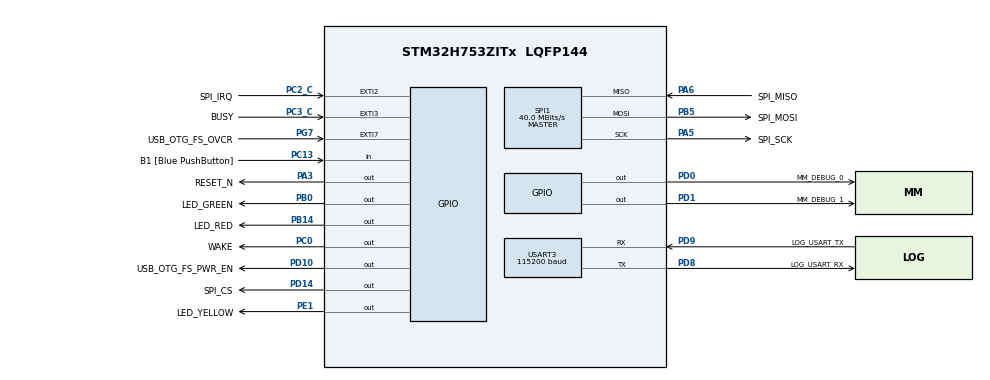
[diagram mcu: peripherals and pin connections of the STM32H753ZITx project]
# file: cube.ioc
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CORTEX_M7.CPU_DCache=Disabled
CORTEX_M7.CPU_ICache=Disabled
CORTEX_M7.MPU_Control=__NULL
Dma.Request0=SPI1_TX
Dma.Request1=SPI1_RX
Dma.SPI1_RX.1.Direction=DMA_PERIPH_TO_MEMORY
Dma.SPI1_RX.1.EventEnable=DISABLE
Dma.SPI1_RX.1.FIFOMode=DMA_FIFOMODE_ENABLE
Dma.SPI1_RX.1.FIFOThreshold=DMA_FIFO_THRESHOLD_FULL
Dma.SPI1_RX.1.Instance=DMA1_Stream1
Dma.SPI1_RX.1.MemBurst=DMA_MBURST_SINGLE
Dma.SPI1_RX.1.MemDataAlignment=DMA_MDATAALIGN_BYTE
Dma.SPI1_RX.1.MemInc=DMA_MINC_ENABLE
Dma.SPI1_RX.1.Mode=DMA_NORMAL
Dma.SPI1_RX.1.PeriphBurst=DMA_PBURST_SINGLE
Dma.SPI1_RX.1.PeriphDataAlignment=DMA_PDATAALIGN_BYTE
Dma.SPI1_RX.1.PeriphInc=DMA_PINC_DISABLE
Dma.SPI1_RX.1.Polarity=HAL_DMAMUX_REQ_GEN_RISING
Dma.SPI1_RX.1.Priority=DMA_PRIORITY_LOW
Dma.SPI1_RX.1.RequestNumber=1
Dma.SPI1_RX.1.SignalID=NONE
Dma.SPI1_RX.1.SyncEnable=DISABLE
Dma.SPI1_RX.1.SyncPolarity=HAL_DMAMUX_SYNC_NO_EVENT
Dma.SPI1_RX.1.SyncRequestNumber=1
Dma.SPI1_RX.1.SyncSignalID=NONE
Dma.SPI1_TX.0.Direction=DMA_MEMORY_TO_PERIPH
Dma.SPI1_TX.0.EventEnable=DISABLE
Dma.SPI1_TX.0.FIFOMode=DMA_FIFOMODE_ENABLE
Dma.SPI1_TX.0.FIFOThreshold=DMA_FIFO_THRESHOLD_FULL
Dma.SPI1_TX.0.Instance=DMA1_Stream0
Dma.SPI1_TX.0.MemBurst=DMA_MBURST_SINGLE
Dma.SPI1_TX.0.MemDataAlignment=DMA_MDATAALIGN_BYTE
Dma.SPI1_TX.0.MemInc=DMA_MINC_ENABLE
Dma.SPI1_TX.0.Mode=DMA_NORMAL
Dma.SPI1_TX.0.PeriphBurst=DMA_PBURST_SINGLE
Dma.SPI1_TX.0.PeriphDataAlignment=DMA_PDATAALIGN_BYTE
Dma.SPI1_TX.0.PeriphInc=DMA_PINC_DISABLE
Dma.SPI1_TX.0.Polarity=HAL_DMAMUX_REQ_GEN_RISING
Dma.SPI1_TX.0.Priority=DMA_PRIORITY_LOW
Dma.SPI1_TX.0.RequestNumber=1
Dma.SPI1_TX.0.SignalID=NONE
Dma.SPI1_TX.0.SyncEnable=DISABLE
Dma.SPI1_TX.0.SyncPolarity=HAL_DMAMUX_SYNC_NO_EVENT
Dma.SPI1_TX.0.SyncRequestNumber=1
Dma.SPI1_TX.0.SyncSignalID=NONE
LPTIM1.ClockPrescaler=LPTIM_PRESCALER_DIV4
Mcu.Family=STM32H7
Mcu.Name=STM32H753ZITx
Mcu.Package=LQFP144
NVIC.DMA1_Stream0_IRQn=true\:0\:0\:false\:false\:false\:false\:true\:true
NVIC.DMA1_Stream1_IRQn=true\:15\:0\:true\:false\:false\:false\:true\:true
NVIC.EXTI2_IRQn=true\:15\:0\:true\:false\:false\:true\:true\:false
NVIC.EXTI3_IRQn=true\:15\:0\:true\:false\:false\:true\:true\:false
NVIC.LPTIM1_IRQn=true\:0\:0\:false\:false\:true\:true\:true\:true
NVIC.PriorityGroup=NVIC_PRIORITYGROUP_4
NVIC.SPI1_IRQn=true\:0\:0\:false\:false\:false\:false\:true\:true
NVIC.TIM1_UP_IRQn=true\:15\:0\:false\:false\:true\:false\:true\:true
NVIC.TimeBase=TIM1_UP_IRQn
NVIC.TimeBaseIP=TIM1
NVIC.USART3_IRQn=true\:15\:0\:true\:false\:false\:true\:true\:true
PA11.Signal=USB_OTG_FS_DM
PA12.Signal=USB_OTG_FS_DP
PA3.GPIO_Label=RESET_N
PA3.Signal=GPIO_Output
PA5.GPIO_Label=SPI_SCK
PA5.GPIO_Speed=GPIO_SPEED_FREQ_VERY_HIGH
PA5.Mode=Full_Duplex_Master
PA5.Signal=SPI1_SCK
PA6.GPIO_Label=SPI_MISO
PA6.GPIO_Speed=GPIO_SPEED_FREQ_VERY_HIGH
PA6.Mode=Full_Duplex_Master
PA6.Signal=SPI1_MISO
PA9.Signal=USB_OTG_FS_VBUS
PB0.GPIO_Label=LED_GREEN
PB0.Signal=GPIO_Output
PB14.GPIO_Label=LED_RED
PB14.Signal=GPIO_Output
PB5.GPIO_Label=SPI_MOSI
PB5.GPIO_Speed=GPIO_SPEED_FREQ_VERY_HIGH
PB5.Mode=Full_Duplex_Master
PB5.Signal=SPI1_MOSI
PC0.GPIO_Label=WAKE
PC0.Signal=GPIO_Output
PC13.GPIO_Label=B1 [Blue PushButton]
PC13.Signal=GPIO_Input
PC14-OSC32_IN\ (OSC32_IN).Mode=LSE-External-Oscillator
PC14-OSC32_IN\ (OSC32_IN).Signal=RCC_OSC32_IN
PC15-OSC32_OUT\ (OSC32_OUT).Mode=LSE-External-Oscillator
PC15-OSC32_OUT\ (OSC32_OUT).Signal=RCC_OSC32_OUT
PC2_C.GPIO_Label=SPI_IRQ
PC2_C.GPIO_ModeDefaultEXTI=GPIO_MODE_IT_FALLING
PC2_C.Signal=GPXTI2
PC3_C.GPIO_Label=BUSY
PC3_C.GPIO_PuPd=GPIO_PULLDOWN
PC3_C.Signal=GPXTI3
PD0.GPIO_Label=MM_DEBUG_0
PD0.Signal=GPIO_Output
PD1.GPIO_Label=MM_DEBUG_1
PD1.Signal=GPIO_Output
PD10.GPIO_Label=USB_OTG_FS_PWR_EN
PD10.Signal=GPIO_Output
PD14.GPIO_Label=SPI_CS
PD14.Signal=GPIO_Output
PD8.GPIO_Label=LOG_USART_RX
PD8.Mode=Asynchronous
PD8.Signal=USART3_TX
PD9.GPIO_Label=LOG_USART_TX
PD9.Mode=Asynchronous
PD9.Signal=USART3_RX
PE1.GPIO_Label=LED_YELLOW
PE1.Signal=GPIO_Output
PG7.GPIO_Label=USB_OTG_FS_OVCR
PG7.Signal=GPXTI7
PH0-OSC_IN\ (PH0).Mode=HSE-External-Clock-Source
PH0-OSC_IN\ (PH0).Signal=RCC_OSC_IN
PH1-OSC_OUT\ (PH1).Signal=RCC_OSC_OUT
ProjectManager.HeapSize=0x200
ProjectManager.StackSize=0x400
ProjectManager.TargetToolchain=STM32CubeIDE
RCC.ADCFreq_Value=160000000
RCC.APB1Freq_Value=120000000
RCC.APB2Freq_Value=120000000
RCC.APB3Freq_Value=120000000
RCC.APB4Freq_Value=120000000
RCC.CortexFreq_Value=480000000
RCC.D1PPRE=RCC_APB3_DIV2
RCC.D2PPRE1=RCC_APB1_DIV2
RCC.D2PPRE2=RCC_APB2_DIV2
RCC.D3PPRE=RCC_APB4_DIV2
RCC.DIVM1=2
RCC.DIVM2=1
RCC.DIVN1=240
RCC.DIVN2=40
RCC.DIVQ1=4
RCC.HCLKFreq_Value=240000000
RCC.HPRE=RCC_HCLK_DIV2
RCC.HSE_VALUE=8000000
RCC.PLLFRACN=0
RCC.PLLSourceVirtual=RCC_PLLSOURCE_HSE
RCC.PWR_Regulator_Voltage_Scale=PWR_REGULATOR_VOLTAGE_SCALE0
RCC.SPI123CLockSelection=RCC_SPI123CLKSOURCE_PLL2
RCC.SYSCLKFreq_VALUE=480000000
RCC.SYSCLKSource=RCC_SYSCLKSOURCE_PLLCLK
RCC.USBCLockSelection=RCC_USBCLKSOURCE_HSI48
RCC.USBFreq_Value=48000000
SPI1.BaudRatePrescaler=SPI_BAUDRATEPRESCALER_4
SPI1.CalculateBaudRate=40.0 MBits/s
SPI1.DataSize=SPI_DATASIZE_8BIT
SPI1.Direction=SPI_DIRECTION_2LINES
SPI1.Mode=SPI_MODE_MASTER
SPI1.NSSPMode=SPI_NSS_PULSE_DISABLE
SPI1.VirtualType=VM_MASTER
USART3.AutoBaudRateEnableParam=UART_ADVFEATURE_AUTOBAUDRATE_DISABLE
USART3.BaudRate=115200
USART3.ClockPrescaler=PRESCALER_DIV1
USART3.DMADisableonRxErrorParam=ADVFEATURE_DMA_ENABLEONRXERROR
USART3.DataInvertParam=ADVFEATURE_DATAINV_DISABLE
USART3.FIFOMode=FIFOMODE_DISABLE
USART3.MSBFirstParam=ADVFEATURE_MSBFIRST_DISABLE
USART3.Mode=MODE_TX_RX
USART3.OneBitSampling=UART_ONE_BIT_SAMPLE_DISABLE
USART3.OverSampling=UART_OVERSAMPLING_16
USART3.OverrunDisableParam=ADVFEATURE_OVERRUN_ENABLE
USART3.Parity=PARITY_NONE
USART3.RXFIFOThreshold=RXFIFO_THRESHOLD_1EIGHTHFULL
USART3.RxPinLevelInvertParam=ADVFEATURE_RXINV_DISABLE
USART3.StopBits=STOPBITS_1
USART3.SwapParam=ADVFEATURE_SWAP_DISABLE
USART3.TXFIFOThreshold=TXFIFO_THRESHOLD_1EIGHTHFULL
USART3.TxPinLevelInvertParam=ADVFEATURE_TXINV_DISABLE
USART3.VirtualMode-Asynchronous=VM_ASYNC
USART3.WordLength=WORDLENGTH_8B
VP_LPTIM1_VS_LPTIM_counterModeInternalClock.Mode=Counts__internal_clock_event_00
VP_RNG_VS_RNG.Mode=RNG_Activate
VP_RTC_VS_RTC_Activate.Mode=RTC_Enabled
VP_SYS_VS_tim1.Mode=TIM1
board=NUCLEO-H753ZI

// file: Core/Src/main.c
/* USER CODE BEGIN Header */
/**
  ******************************************************************************
  * @file           : main.c
  * @brief          : Main program body
  ******************************************************************************
  * @attention
  *
  * Copyright (c) 2024 STMicroelectronics.
  * All rights reserved.
  *
  * This software is licensed under terms that can be found in the LICENSE file
  * in the root directory of this software component.
  * If no LICENSE file comes with this software, it is provided AS-IS.
  *
  ******************************************************************************
  */
/* USER CODE END Header */
#include "main.h"

/* USER CODE BEGIN Includes */
#include "mmosal.h"
/* USER CODE END Includes */

RNG_HandleTypeDef hrng;

void SystemClock_Config(void);
static void MX_GPIO_Init(void);
static void MX_DMA_Init(void);
static void MX_LPTIM1_Init(void);
static void MX_RTC_Init(void);
static void MX_SPI1_Init(void);
static void MX_USART3_UART_Init(void);
static void MX_RNG_Init(void);
/* USER CODE BEGIN PFP */
void app_init(void);

/* USER CODE END PFP */

int main(void)
{

  /* MCU Configuration--------------------------------------------------------*/

  /* Reset of all peripherals, Initializes the Flash interface and the Systick. */
  HAL_Init();

  /* Configure the system clock */
  SystemClock_Config();

  /* Initialize all configured peripherals */
  MX_GPIO_Init();
  MX_DMA_Init();
  MX_LPTIM1_Init();
  MX_RTC_Init();
  MX_SPI1_Init();
  MX_USART3_UART_Init();
  MX_RNG_Init();
  /* USER CODE BEGIN 2 */

  mmosal_main(app_init);

  /* USER CODE END 2 */

  /* Infinite loop */
  while (1)
  {

  }
}

void SystemClock_Config(void)
{
  RCC_OscInitTypeDef RCC_OscInitStruct = {0};
  RCC_ClkInitTypeDef RCC_ClkInitStruct = {0};

  /** Supply configuration update enable
  */
  HAL_PWREx_ConfigSupply(PWR_LDO_SUPPLY);

  /** Configure the main internal regulator output voltage
  */
  __HAL_PWR_VOLTAGESCALING_CONFIG(PWR_REGULATOR_VOLTAGE_SCALE0);

  while(!__HAL_PWR_GET_FLAG(PWR_FLAG_VOSRDY)) {}

  /** Initializes the RCC Oscillators according to the specified parameters
  * in the RCC_OscInitTypeDef structure.
  */
  RCC_OscInitStruct.OscillatorType = RCC_OSCILLATORTYPE_HSI48|RCC_OSCILLATORTYPE_LSI
                              |RCC_OSCILLATORTYPE_HSE;
  RCC_OscInitStruct.HSEState = RCC_HSE_BYPASS;
  RCC_OscInitStruct.LSIState = RCC_LSI_ON;
  RCC_OscInitStruct.HSI48State = RCC_HSI48_ON;
  RCC_OscInitStruct.PLL.PLLState = RCC_PLL_ON;
  RCC_OscInitStruct.PLL.PLLSource = RCC_PLLSOURCE_HSE;
  RCC_OscInitStruct.PLL.PLLM = 2;
  RCC_OscInitStruct.PLL.PLLN = 240;
  RCC_OscInitStruct.PLL.PLLP = 2;
  RCC_OscInitStruct.PLL.PLLQ = 4;
  RCC_OscInitStruct.PLL.PLLR = 2;
  RCC_OscInitStruct.PLL.PLLRGE = RCC_PLL1VCIRANGE_2;
  RCC_OscInitStruct.PLL.PLLVCOSEL = RCC_PLL1VCOWIDE;
  RCC_OscInitStruct.PLL.PLLFRACN = 0;
  if (HAL_RCC_OscConfig(&RCC_OscInitStruct) != HAL_OK)
  {
    Error_Handler();
  }

  /** Initializes the CPU, AHB and APB buses clocks
  */
  RCC_ClkInitStruct.ClockType = RCC_CLOCKTYPE_HCLK|RCC_CLOCKTYPE_SYSCLK
                              |RCC_CLOCKTYPE_PCLK1|RCC_CLOCKTYPE_PCLK2
                              |RCC_CLOCKTYPE_D3PCLK1|RCC_CLOCKTYPE_D1PCLK1;
  RCC_ClkInitStruct.SYSCLKSource = RCC_SYSCLKSOURCE_PLLCLK;
  RCC_ClkInitStruct.SYSCLKDivider = RCC_SYSCLK_DIV1;
  RCC_ClkInitStruct.AHBCLKDivider = RCC_HCLK_DIV2;
  RCC_ClkInitStruct.APB3CLKDivider = RCC_APB3_DIV2;
  RCC_ClkInitStruct.APB1CLKDivider = RCC_APB1_DIV2;
  RCC_ClkInitStruct.APB2CLKDivider = RCC_APB2_DIV2;
  RCC_ClkInitStruct.APB4CLKDivider = RCC_APB4_DIV2;

  if (HAL_RCC_ClockConfig(&RCC_ClkInitStruct, FLASH_LATENCY_4) != HAL_OK)
  {
    Error_Handler();
  }
}

static void MX_LPTIM1_Init(void)
{

  RCC_PeriphCLKInitTypeDef PeriphClkInitStruct = {0};

  /** Initializes the peripherals clock
  */
  PeriphClkInitStruct.PeriphClockSelection = RCC_PERIPHCLK_LPTIM1;
  PeriphClkInitStruct.Lptim1ClockSelection = RCC_LPTIM1CLKSOURCE_D2PCLK1;
  if (HAL_RCCEx_PeriphCLKConfig(&PeriphClkInitStruct) != HAL_OK)
  {
    Error_Handler();
  }

  /* Peripheral clock enable */
  LL_APB1_GRP1_EnableClock(LL_APB1_GRP1_PERIPH_LPTIM1);

  /* LPTIM1 interrupt Init */
  NVIC_SetPriority(LPTIM1_IRQn, NVIC_EncodePriority(NVIC_GetPriorityGrouping(),0, 0));
  NVIC_EnableIRQ(LPTIM1_IRQn);

  LL_LPTIM_SetClockSource(LPTIM1, LL_LPTIM_CLK_SOURCE_INTERNAL);
  LL_LPTIM_SetPrescaler(LPTIM1, LL_LPTIM_PRESCALER_DIV4);
  LL_LPTIM_SetPolarity(LPTIM1, LL_LPTIM_OUTPUT_POLARITY_REGULAR);
  LL_LPTIM_SetUpdateMode(LPTIM1, LL_LPTIM_UPDATE_MODE_IMMEDIATE);
  LL_LPTIM_SetCounterMode(LPTIM1, LL_LPTIM_COUNTER_MODE_INTERNAL);
  LL_LPTIM_TrigSw(LPTIM1);
  LL_LPTIM_SetInput1Src(LPTIM1, LL_LPTIM_INPUT1_SRC_GPIO);
  LL_LPTIM_SetInput2Src(LPTIM1, LL_LPTIM_INPUT2_SRC_GPIO);

}

static void MX_RNG_Init(void)
{

  hrng.Instance = RNG;
  hrng.Init.ClockErrorDetection = RNG_CED_ENABLE;
  if (HAL_RNG_Init(&hrng) != HAL_OK)
  {
    Error_Handler();
  }

}

static void MX_RTC_Init(void)
{

  LL_RTC_InitTypeDef RTC_InitStruct = {0};

  RCC_PeriphCLKInitTypeDef PeriphClkInitStruct = {0};

  /** Initializes the peripherals clock
  */
  PeriphClkInitStruct.PeriphClockSelection = RCC_PERIPHCLK_RTC;
  PeriphClkInitStruct.RTCClockSelection = RCC_RTCCLKSOURCE_LSI;
  if (HAL_RCCEx_PeriphCLKConfig(&PeriphClkInitStruct) != HAL_OK)
  {
    Error_Handler();
  }

  /* Peripheral clock enable */
  LL_RCC_EnableRTC();

  RTC_InitStruct.HourFormat = LL_RTC_HOURFORMAT_24HOUR;
  RTC_InitStruct.AsynchPrescaler = 127;
  RTC_InitStruct.SynchPrescaler = 255;
  LL_RTC_Init(RTC, &RTC_InitStruct);

}

static void MX_SPI1_Init(void)
{

  LL_SPI_InitTypeDef SPI_InitStruct = {0};

  LL_GPIO_InitTypeDef GPIO_InitStruct = {0};
  RCC_PeriphCLKInitTypeDef PeriphClkInitStruct = {0};

  /** Initializes the peripherals clock
  */
  PeriphClkInitStruct.PeriphClockSelection = RCC_PERIPHCLK_SPI1;
  PeriphClkInitStruct.PLL2.PLL2M = 1;
  PeriphClkInitStruct.PLL2.PLL2N = 40;
  PeriphClkInitStruct.PLL2.PLL2P = 2;
  PeriphClkInitStruct.PLL2.PLL2Q = 2;
  PeriphClkInitStruct.PLL2.PLL2R = 2;
  PeriphClkInitStruct.PLL2.PLL2RGE = RCC_PLL2VCIRANGE_3;
  PeriphClkInitStruct.PLL2.PLL2VCOSEL = RCC_PLL2VCOWIDE;
  PeriphClkInitStruct.PLL2.PLL2FRACN = 0;
  PeriphClkInitStruct.Spi123ClockSelection = RCC_SPI123CLKSOURCE_PLL2;
  if (HAL_RCCEx_PeriphCLKConfig(&PeriphClkInitStruct) != HAL_OK)
  {
    Error_Handler();
  }

  /* Peripheral clock enable */
  LL_APB2_GRP1_EnableClock(LL_APB2_GRP1_PERIPH_SPI1);

  LL_AHB4_GRP1_EnableClock(LL_AHB4_GRP1_PERIPH_GPIOA);
  LL_AHB4_GRP1_EnableClock(LL_AHB4_GRP1_PERIPH_GPIOB);
  /**SPI1 GPIO Configuration
  PA5   ------> SPI1_SCK
  PA6   ------> SPI1_MISO
  PB5   ------> SPI1_MOSI
  */
  GPIO_InitStruct.Pin = SPI_SCK_Pin|SPI_MISO_Pin;
  GPIO_InitStruct.Mode = LL_GPIO_MODE_ALTERNATE;
  GPIO_InitStruct.Speed = LL_GPIO_SPEED_FREQ_VERY_HIGH;
  GPIO_InitStruct.OutputType = LL_GPIO_OUTPUT_PUSHPULL;
  GPIO_InitStruct.Pull = LL_GPIO_PULL_NO;
  GPIO_InitStruct.Alternate = LL_GPIO_AF_5;
  LL_GPIO_Init(GPIOA, &GPIO_InitStruct);

  GPIO_InitStruct.Pin = SPI_MOSI_Pin;
  GPIO_InitStruct.Mode = LL_GPIO_MODE_ALTERNATE;
  GPIO_InitStruct.Speed = LL_GPIO_SPEED_FREQ_VERY_HIGH;
  GPIO_InitStruct.OutputType = LL_GPIO_OUTPUT_PUSHPULL;
  GPIO_InitStruct.Pull = LL_GPIO_PULL_NO;
  GPIO_InitStruct.Alternate = LL_GPIO_AF_5;
  LL_GPIO_Init(SPI_MOSI_GPIO_Port, &GPIO_InitStruct);

  /* SPI1 DMA Init */

  /* SPI1_TX Init */
  LL_DMA_SetPeriphRequest(DMA1, LL_DMA_STREAM_0, LL_DMAMUX1_REQ_SPI1_TX);

  LL_DMA_SetDataTransferDirection(DMA1, LL_DMA_STREAM_0, LL_DMA_DIRECTION_MEMORY_TO_PERIPH);

  LL_DMA_SetStreamPriorityLevel(DMA1, LL_DMA_STREAM_0, LL_DMA_PRIORITY_LOW);

  LL_DMA_SetMode(DMA1, LL_DMA_STREAM_0, LL_DMA_MODE_NORMAL);

  LL_DMA_SetPeriphIncMode(DMA1, LL_DMA_STREAM_0, LL_DMA_PERIPH_NOINCREMENT);

  LL_DMA_SetMemoryIncMode(DMA1, LL_DMA_STREAM_0, LL_DMA_MEMORY_INCREMENT);

  LL_DMA_SetPeriphSize(DMA1, LL_DMA_STREAM_0, LL_DMA_PDATAALIGN_BYTE);

  LL_DMA_SetMemorySize(DMA1, LL_DMA_STREAM_0, LL_DMA_MDATAALIGN_BYTE);

  LL_DMA_EnableFifoMode(DMA1, LL_DMA_STREAM_0);

  LL_DMA_SetFIFOThreshold(DMA1, LL_DMA_STREAM_0, LL_DMA_FIFOTHRESHOLD_FULL);

  LL_DMA_SetMemoryBurstxfer(DMA1, LL_DMA_STREAM_0, LL_DMA_MBURST_SINGLE);

  LL_DMA_SetPeriphBurstxfer(DMA1, LL_DMA_STREAM_0, LL_DMA_PBURST_SINGLE);

  /* SPI1_RX Init */
  LL_DMA_SetPeriphRequest(DMA1, LL_DMA_STREAM_1, LL_DMAMUX1_REQ_SPI1_RX);

  LL_DMA_SetDataTransferDirection(DMA1, LL_DMA_STREAM_1, LL_DMA_DIRECTION_PERIPH_TO_MEMORY);

  LL_DMA_SetStreamPriorityLevel(DMA1, LL_DMA_STREAM_1, LL_DMA_PRIORITY_LOW);

  LL_DMA_SetMode(DMA1, LL_DMA_STREAM_1, LL_DMA_MODE_NORMAL);

  LL_DMA_SetPeriphIncMode(DMA1, LL_DMA_STREAM_1, LL_DMA_PERIPH_NOINCREMENT);

  LL_DMA_SetMemoryIncMode(DMA1, LL_DMA_STREAM_1, LL_DMA_MEMORY_INCREMENT);

  LL_DMA_SetPeriphSize(DMA1, LL_DMA_STREAM_1, LL_DMA_PDATAALIGN_BYTE);

  LL_DMA_SetMemorySize(DMA1, LL_DMA_STREAM_1, LL_DMA_MDATAALIGN_BYTE);

  LL_DMA_EnableFifoMode(DMA1, LL_DMA_STREAM_1);

  LL_DMA_SetFIFOThreshold(DMA1, LL_DMA_STREAM_1, LL_DMA_FIFOTHRESHOLD_FULL);

  LL_DMA_SetMemoryBurstxfer(DMA1, LL_DMA_STREAM_1, LL_DMA_MBURST_SINGLE);

  LL_DMA_SetPeriphBurstxfer(DMA1, LL_DMA_STREAM_1, LL_DMA_PBURST_SINGLE);

  /* SPI1 interrupt Init */
  NVIC_SetPriority(SPI1_IRQn, NVIC_EncodePriority(NVIC_GetPriorityGrouping(),0, 0));
  NVIC_EnableIRQ(SPI1_IRQn);

  /* USER CODE BEGIN SPI1_Init 1 */

  LL_DMA_EnableIT_TC(SPI_DMA_PERIPH, SPI_RX_DMA_STREAM);
  LL_DMA_EnableIT_TC(SPI_DMA_PERIPH, SPI_TX_DMA_STREAM);

  /* USER CODE END SPI1_Init 1 */
  /* SPI1 parameter configuration*/
  SPI_InitStruct.TransferDirection = LL_SPI_FULL_DUPLEX;
  SPI_InitStruct.Mode = LL_SPI_MODE_MASTER;
  SPI_InitStruct.DataWidth = LL_SPI_DATAWIDTH_8BIT;
  SPI_InitStruct.ClockPolarity = LL_SPI_POLARITY_LOW;
  SPI_InitStruct.ClockPhase = LL_SPI_PHASE_1EDGE;
  SPI_InitStruct.NSS = LL_SPI_NSS_SOFT;
  SPI_InitStruct.BaudRate = LL_SPI_BAUDRATEPRESCALER_DIV4;
  SPI_InitStruct.BitOrder = LL_SPI_MSB_FIRST;
  SPI_InitStruct.CRCCalculation = LL_SPI_CRCCALCULATION_DISABLE;
  SPI_InitStruct.CRCPoly = 0x0;
  LL_SPI_Init(SPI1, &SPI_InitStruct);
  LL_SPI_SetStandard(SPI1, LL_SPI_PROTOCOL_MOTOROLA);
  LL_SPI_SetFIFOThreshold(SPI1, LL_SPI_FIFO_TH_01DATA);
  LL_SPI_DisableNSSPulseMgt(SPI1);

}

static void MX_USART3_UART_Init(void)
{

  LL_USART_InitTypeDef USART_InitStruct = {0};

  LL_GPIO_InitTypeDef GPIO_InitStruct = {0};
  RCC_PeriphCLKInitTypeDef PeriphClkInitStruct = {0};

  /** Initializes the peripherals clock
  */
  PeriphClkInitStruct.PeriphClockSelection = RCC_PERIPHCLK_USART3;
  PeriphClkInitStruct.Usart234578ClockSelection = RCC_USART234578CLKSOURCE_D2PCLK1;
  if (HAL_RCCEx_PeriphCLKConfig(&PeriphClkInitStruct) != HAL_OK)
  {
    Error_Handler();
  }

  /* Peripheral clock enable */
  LL_APB1_GRP1_EnableClock(LL_APB1_GRP1_PERIPH_USART3);

  LL_AHB4_GRP1_EnableClock(LL_AHB4_GRP1_PERIPH_GPIOD);
  /**USART3 GPIO Configuration
  PD8   ------> USART3_TX
  PD9   ------> USART3_RX
  */
  GPIO_InitStruct.Pin = LOG_USART_RX_Pin|LOG_USART_TX_Pin;
  GPIO_InitStruct.Mode = LL_GPIO_MODE_ALTERNATE;
  GPIO_InitStruct.Speed = LL_GPIO_SPEED_FREQ_LOW;
  GPIO_InitStruct.OutputType = LL_GPIO_OUTPUT_PUSHPULL;
  GPIO_InitStruct.Pull = LL_GPIO_PULL_NO;
  GPIO_InitStruct.Alternate = LL_GPIO_AF_7;
  LL_GPIO_Init(GPIOD, &GPIO_InitStruct);

  /* USART3 interrupt Init */
  NVIC_SetPriority(USART3_IRQn, NVIC_EncodePriority(NVIC_GetPriorityGrouping(),15, 0));
  NVIC_EnableIRQ(USART3_IRQn);

  USART_InitStruct.PrescalerValue = LL_USART_PRESCALER_DIV1;
  USART_InitStruct.BaudRate = 115200;
  USART_InitStruct.DataWidth = LL_USART_DATAWIDTH_8B;
  USART_InitStruct.StopBits = LL_USART_STOPBITS_1;
  USART_InitStruct.Parity = LL_USART_PARITY_NONE;
  USART_InitStruct.TransferDirection = LL_USART_DIRECTION_TX_RX;
  USART_InitStruct.HardwareFlowControl = LL_USART_HWCONTROL_NONE;
  USART_InitStruct.OverSampling = LL_USART_OVERSAMPLING_16;
  LL_USART_Init(USART3, &USART_InitStruct);
  LL_USART_SetTXFIFOThreshold(USART3, LL_USART_FIFOTHRESHOLD_1_8);
  LL_USART_SetRXFIFOThreshold(USART3, LL_USART_FIFOTHRESHOLD_1_8);
  LL_USART_DisableFIFO(USART3);
  LL_USART_ConfigAsyncMode(USART3);

  LL_USART_Enable(USART3);

  /* Polling USART3 initialisation */
  while((!(LL_USART_IsActiveFlag_TEACK(USART3))) || (!(LL_USART_IsActiveFlag_REACK(USART3))))
  {
  }

}

static void MX_DMA_Init(void)
{

  /* Init with LL driver */
  /* DMA controller clock enable */
  LL_AHB1_GRP1_EnableClock(LL_AHB1_GRP1_PERIPH_DMA1);

  /* DMA interrupt init */
  /* DMA1_Stream0_IRQn interrupt configuration */
  NVIC_SetPriority(DMA1_Stream0_IRQn, NVIC_EncodePriority(NVIC_GetPriorityGrouping(),0, 0));
  NVIC_EnableIRQ(DMA1_Stream0_IRQn);
  /* DMA1_Stream1_IRQn interrupt configuration */
  NVIC_SetPriority(DMA1_Stream1_IRQn, NVIC_EncodePriority(NVIC_GetPriorityGrouping(),15, 0));
  NVIC_EnableIRQ(DMA1_Stream1_IRQn);

}

static void MX_GPIO_Init(void)
{
  LL_EXTI_InitTypeDef EXTI_InitStruct = {0};
  LL_GPIO_InitTypeDef GPIO_InitStruct = {0};

  /* GPIO Ports Clock Enable */
  LL_AHB4_GRP1_EnableClock(LL_AHB4_GRP1_PERIPH_GPIOC);
  LL_AHB4_GRP1_EnableClock(LL_AHB4_GRP1_PERIPH_GPIOH);
  LL_AHB4_GRP1_EnableClock(LL_AHB4_GRP1_PERIPH_GPIOA);
  LL_AHB4_GRP1_EnableClock(LL_AHB4_GRP1_PERIPH_GPIOB);
  LL_AHB4_GRP1_EnableClock(LL_AHB4_GRP1_PERIPH_GPIOD);
  LL_AHB4_GRP1_EnableClock(LL_AHB4_GRP1_PERIPH_GPIOG);
  LL_AHB4_GRP1_EnableClock(LL_AHB4_GRP1_PERIPH_GPIOE);

  /**/
  LL_GPIO_ResetOutputPin(WAKE_GPIO_Port, WAKE_Pin);

  /**/
  LL_GPIO_ResetOutputPin(RESET_N_GPIO_Port, RESET_N_Pin);

  /**/
  LL_GPIO_ResetOutputPin(GPIOB, LED_GREEN_Pin|LED_RED_Pin);

  /**/
  LL_GPIO_ResetOutputPin(GPIOD, USB_OTG_FS_PWR_EN_Pin|SPI_CS_Pin|MM_DEBUG_0_Pin|MM_DEBUG_1_Pin);

  /**/
  LL_GPIO_ResetOutputPin(LED_YELLOW_GPIO_Port, LED_YELLOW_Pin);

  /**/
  GPIO_InitStruct.Pin = B1_Pin;
  GPIO_InitStruct.Mode = LL_GPIO_MODE_INPUT;
  GPIO_InitStruct.Pull = LL_GPIO_PULL_NO;
  LL_GPIO_Init(B1_GPIO_Port, &GPIO_InitStruct);

  /**/
  GPIO_InitStruct.Pin = WAKE_Pin;
  GPIO_InitStruct.Mode = LL_GPIO_MODE_OUTPUT;
  GPIO_InitStruct.Speed = LL_GPIO_SPEED_FREQ_LOW;
  GPIO_InitStruct.OutputType = LL_GPIO_OUTPUT_PUSHPULL;
  GPIO_InitStruct.Pull = LL_GPIO_PULL_NO;
  LL_GPIO_Init(WAKE_GPIO_Port, &GPIO_InitStruct);

  /**/
  GPIO_InitStruct.Pin = RESET_N_Pin;
  GPIO_InitStruct.Mode = LL_GPIO_MODE_OUTPUT;
  GPIO_InitStruct.Speed = LL_GPIO_SPEED_FREQ_LOW;
  GPIO_InitStruct.OutputType = LL_GPIO_OUTPUT_PUSHPULL;
  GPIO_InitStruct.Pull = LL_GPIO_PULL_NO;
  LL_GPIO_Init(RESET_N_GPIO_Port, &GPIO_InitStruct);

  /**/
  GPIO_InitStruct.Pin = LED_GREEN_Pin|LED_RED_Pin;
  GPIO_InitStruct.Mode = LL_GPIO_MODE_OUTPUT;
  GPIO_InitStruct.Speed = LL_GPIO_SPEED_FREQ_LOW;
  GPIO_InitStruct.OutputType = LL_GPIO_OUTPUT_PUSHPULL;
  GPIO_InitStruct.Pull = LL_GPIO_PULL_NO;
  LL_GPIO_Init(GPIOB, &GPIO_InitStruct);

  /**/
  GPIO_InitStruct.Pin = USB_OTG_FS_PWR_EN_Pin|SPI_CS_Pin|MM_DEBUG_0_Pin|MM_DEBUG_1_Pin;
  GPIO_InitStruct.Mode = LL_GPIO_MODE_OUTPUT;
  GPIO_InitStruct.Speed = LL_GPIO_SPEED_FREQ_LOW;
  GPIO_InitStruct.OutputType = LL_GPIO_OUTPUT_PUSHPULL;
  GPIO_InitStruct.Pull = LL_GPIO_PULL_NO;
  LL_GPIO_Init(GPIOD, &GPIO_InitStruct);

  /**/
  GPIO_InitStruct.Pin = LL_GPIO_PIN_11|LL_GPIO_PIN_12;
  GPIO_InitStruct.Mode = LL_GPIO_MODE_ALTERNATE;
  GPIO_InitStruct.Speed = LL_GPIO_SPEED_FREQ_LOW;
  GPIO_InitStruct.OutputType = LL_GPIO_OUTPUT_PUSHPULL;
  GPIO_InitStruct.Pull = LL_GPIO_PULL_NO;
  GPIO_InitStruct.Alternate = LL_GPIO_AF_10;
  LL_GPIO_Init(GPIOA, &GPIO_InitStruct);

  /**/
  GPIO_InitStruct.Pin = LED_YELLOW_Pin;
  GPIO_InitStruct.Mode = LL_GPIO_MODE_OUTPUT;
  GPIO_InitStruct.Speed = LL_GPIO_SPEED_FREQ_LOW;
  GPIO_InitStruct.OutputType = LL_GPIO_OUTPUT_PUSHPULL;
  GPIO_InitStruct.Pull = LL_GPIO_PULL_NO;
  LL_GPIO_Init(LED_YELLOW_GPIO_Port, &GPIO_InitStruct);

  /**/
  LL_SYSCFG_SetEXTISource(LL_SYSCFG_EXTI_PORTC, LL_SYSCFG_EXTI_LINE2);

  /**/
  LL_SYSCFG_SetEXTISource(LL_SYSCFG_EXTI_PORTC, LL_SYSCFG_EXTI_LINE3);

  /**/
  LL_SYSCFG_SetEXTISource(LL_SYSCFG_EXTI_PORTG, LL_SYSCFG_EXTI_LINE7);

  /**/
  EXTI_InitStruct.Line_0_31 = LL_EXTI_LINE_2;
  EXTI_InitStruct.Line_32_63 = LL_EXTI_LINE_NONE;
  EXTI_InitStruct.Line_64_95 = LL_EXTI_LINE_NONE;
  EXTI_InitStruct.LineCommand = ENABLE;
  EXTI_InitStruct.Mode = LL_EXTI_MODE_IT;
  EXTI_InitStruct.Trigger = LL_EXTI_TRIGGER_FALLING;
  LL_EXTI_Init(&EXTI_InitStruct);

  /**/
  EXTI_InitStruct.Line_0_31 = LL_EXTI_LINE_3;
  EXTI_InitStruct.Line_32_63 = LL_EXTI_LINE_NONE;
  EXTI_InitStruct.Line_64_95 = LL_EXTI_LINE_NONE;
  EXTI_InitStruct.LineCommand = ENABLE;
  EXTI_InitStruct.Mode = LL_EXTI_MODE_IT;
  EXTI_InitStruct.Trigger = LL_EXTI_TRIGGER_RISING;
  LL_EXTI_Init(&EXTI_InitStruct);

  /**/
  EXTI_InitStruct.Line_0_31 = LL_EXTI_LINE_7;
  EXTI_InitStruct.Line_32_63 = LL_EXTI_LINE_NONE;
  EXTI_InitStruct.Line_64_95 = LL_EXTI_LINE_NONE;
  EXTI_InitStruct.LineCommand = ENABLE;
  EXTI_InitStruct.Mode = LL_EXTI_MODE_IT;
  EXTI_InitStruct.Trigger = LL_EXTI_TRIGGER_RISING;
  LL_EXTI_Init(&EXTI_InitStruct);

  /**/
  LL_GPIO_SetPinPull(SPI_IRQ_GPIO_Port, SPI_IRQ_Pin, LL_GPIO_PULL_NO);

  /**/
  LL_GPIO_SetPinPull(BUSY_GPIO_Port, BUSY_Pin, LL_GPIO_PULL_DOWN);

  /**/
  LL_GPIO_SetPinPull(USB_OTG_FS_OVCR_GPIO_Port, USB_OTG_FS_OVCR_Pin, LL_GPIO_PULL_NO);

  /**/
  LL_GPIO_SetPinMode(SPI_IRQ_GPIO_Port, SPI_IRQ_Pin, LL_GPIO_MODE_INPUT);

  /**/
  LL_GPIO_SetPinMode(BUSY_GPIO_Port, BUSY_Pin, LL_GPIO_MODE_INPUT);

  /**/
  LL_GPIO_SetPinMode(USB_OTG_FS_OVCR_GPIO_Port, USB_OTG_FS_OVCR_Pin, LL_GPIO_MODE_INPUT);

  /* EXTI interrupt init*/
  NVIC_SetPriority(EXTI2_IRQn, NVIC_EncodePriority(NVIC_GetPriorityGrouping(),15, 0));
  NVIC_SetPriority(EXTI3_IRQn, NVIC_EncodePriority(NVIC_GetPriorityGrouping(),15, 0));

}

void HAL_TIM_PeriodElapsedCallback(TIM_HandleTypeDef *htim)
{
  if (htim->Instance == TIM1)
  {
    HAL_IncTick();
  }
}

void Error_Handler(void)
{
  __disable_irq();
  while (1)
  {
  }
}
